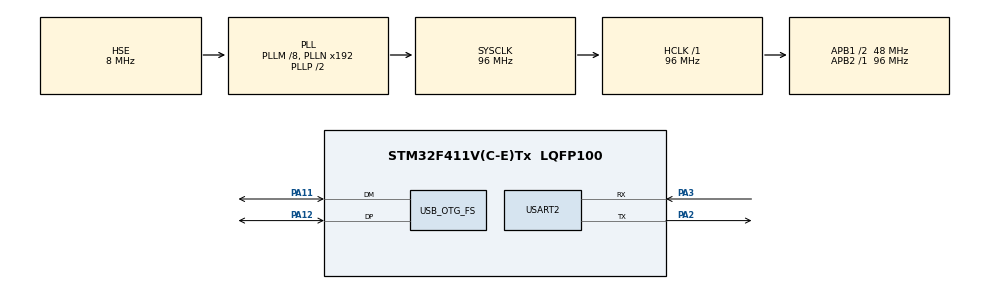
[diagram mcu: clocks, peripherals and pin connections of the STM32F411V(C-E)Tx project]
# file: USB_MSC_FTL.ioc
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Mcu.Family=STM32F4
Mcu.Name=STM32F411V(C-E)Tx
Mcu.Package=LQFP100
NVIC.OTG_FS_IRQn=true\:0\:0\:false\:false\:true\:false\:true\:true
NVIC.PriorityGroup=NVIC_PRIORITYGROUP_4
PA11.Mode=Device_Only
PA11.Signal=USB_OTG_FS_DM
PA12.Mode=Device_Only
PA12.Signal=USB_OTG_FS_DP
PA13.Mode=Serial_Wire
PA13.Signal=SYS_JTMS-SWDIO
PA14.Mode=Serial_Wire
PA14.Signal=SYS_JTCK-SWCLK
PA2.Mode=Asynchronous
PA2.Signal=USART2_TX
PA3.Mode=Asynchronous
PA3.Signal=USART2_RX
PH0\ -\ OSC_IN.Mode=HSE-External-Oscillator
PH0\ -\ OSC_IN.Signal=RCC_OSC_IN
PH1\ -\ OSC_OUT.Mode=HSE-External-Oscillator
PH1\ -\ OSC_OUT.Signal=RCC_OSC_OUT
ProjectManager.HeapSize=0x200
ProjectManager.StackSize=0x400
ProjectManager.TargetToolchain=STM32CubeIDE
RCC.48MHZClocksFreq_Value=48000000
RCC.AHBFreq_Value=96000000
RCC.APB1CLKDivider=RCC_HCLK_DIV2
RCC.APB1Freq_Value=48000000
RCC.APB1TimFreq_Value=96000000
RCC.APB2Freq_Value=96000000
RCC.APB2TimFreq_Value=96000000
RCC.CortexFreq_Value=96000000
RCC.HCLKFreq_Value=96000000
RCC.HSE_VALUE=8000000
RCC.HSI_VALUE=16000000
RCC.LSE_VALUE=32768
RCC.PLLM=8
RCC.SYSCLKFreq_VALUE=96000000
RCC.SYSCLKSource=RCC_SYSCLKSOURCE_PLLCLK
RCC.VCOOutputFreq_Value=192000000
USART2.VirtualMode=VM_ASYNC
USB_DEVICE.CLASS_NAME_FS=MSC
USB_DEVICE.VirtualMode=Msc
USB_DEVICE.VirtualModeFS=Msc_FS
USB_OTG_FS.VirtualMode=Device_Only
VP_USB_DEVICE_VS_USB_DEVICE_MSC_FS.Mode=MSC_FS
board=custom

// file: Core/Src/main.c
/* USER CODE BEGIN Header */
/**
 ******************************************************************************
 * @file           : main.c
 * @brief          : Main program body
 ******************************************************************************
 * @attention
 *
 * Copyright (c) 2025 STMicroelectronics.
 * All rights reserved.
 *
 * This software is licensed under terms that can be found in the LICENSE file
 * in the root directory of this software component.
 * If no LICENSE file comes with this software, it is provided AS-IS.
 *
 ******************************************************************************
 */
/* USER CODE END Header */
#include "main.h"
#include "usart.h"
#include "usb_device.h"
#include "gpio.h"
#include "ftl.h"
#include "nandsim.h"
#include <stdio.h>
#include <stdint.h>
#include <string.h>

/* USER CODE BEGIN PM */
uint8_t write_buf[NAND_PAGE_SIZE];
uint8_t read_buf[NAND_PAGE_SIZE];
/* USER CODE END PM */

void SystemClock_Config(void);

int main(void) {

	/* MCU Configuration--------------------------------------------------------*/

	/* Reset of all peripherals, Initializes the Flash interface and the Systick. */
	HAL_Init();

	/* Configure the system clock */
	SystemClock_Config();

	/* Initialize all configured peripherals */
	MX_GPIO_Init();
	MX_USART2_UART_Init();
	MX_USB_DEVICE_Init();
	/* USER CODE BEGIN 2 */
	FTL_Init();
	printf("FTL Init done\n");

	// 寫入資料
	memset(write_buf, 0, NAND_PAGE_SIZE);
	strcpy((char*) write_buf, "FTL Page Mapping Test");
	printf("Write LPN 5...\n");
	FTL_Write(5, write_buf);

	// 讀出資料
	memset(read_buf, 0, NAND_PAGE_SIZE);
	printf("Read LPN 5...\n");
	FTL_Read(5, read_buf);
	printf("LPN 5 data: %s\n", read_buf);

	// Dump mapping 狀態
	FTL_Dump_Status();
	/* USER CODE END 2 */

	/* Infinite loop */
	while (1) {
		printf("Hello UART\r\n");
		HAL_Delay(1000);
	}
}

void SystemClock_Config(void) {
	RCC_OscInitTypeDef RCC_OscInitStruct = { 0 };
	RCC_ClkInitTypeDef RCC_ClkInitStruct = { 0 };

	/** Configure the main internal regulator output voltage
	 */
	__HAL_RCC_PWR_CLK_ENABLE();
	__HAL_PWR_VOLTAGESCALING_CONFIG(PWR_REGULATOR_VOLTAGE_SCALE1);

	/** Initializes the RCC Oscillators according to the specified parameters
	 * in the RCC_OscInitTypeDef structure.
	 */
	RCC_OscInitStruct.OscillatorType = RCC_OSCILLATORTYPE_HSE;
	RCC_OscInitStruct.HSEState = RCC_HSE_ON;
	RCC_OscInitStruct.PLL.PLLState = RCC_PLL_ON;
	RCC_OscInitStruct.PLL.PLLSource = RCC_PLLSOURCE_HSE;
	RCC_OscInitStruct.PLL.PLLM = 8;
	RCC_OscInitStruct.PLL.PLLN = 192;
	RCC_OscInitStruct.PLL.PLLP = RCC_PLLP_DIV2;
	RCC_OscInitStruct.PLL.PLLQ = 4;
	if (HAL_RCC_OscConfig(&RCC_OscInitStruct) != HAL_OK) {
		Error_Handler();
	}

	/** Initializes the CPU, AHB and APB buses clocks
	 */
	RCC_ClkInitStruct.ClockType = RCC_CLOCKTYPE_HCLK | RCC_CLOCKTYPE_SYSCLK
			| RCC_CLOCKTYPE_PCLK1 | RCC_CLOCKTYPE_PCLK2;
	RCC_ClkInitStruct.SYSCLKSource = RCC_SYSCLKSOURCE_PLLCLK;
	RCC_ClkInitStruct.AHBCLKDivider = RCC_SYSCLK_DIV1;
	RCC_ClkInitStruct.APB1CLKDivider = RCC_HCLK_DIV2;
	RCC_ClkInitStruct.APB2CLKDivider = RCC_HCLK_DIV1;

	if (HAL_RCC_ClockConfig(&RCC_ClkInitStruct, FLASH_LATENCY_3) != HAL_OK) {
		Error_Handler();
	}
}

void Error_Handler(void) {
	__disable_irq();
	while (1) {
	}
}
